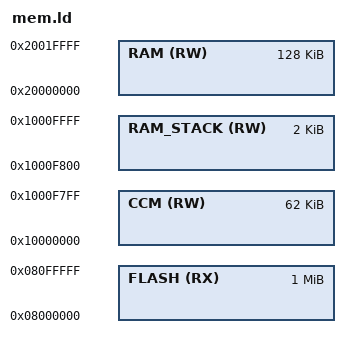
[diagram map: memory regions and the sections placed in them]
MEMORY
{
    FLASH (RX)     : ORIGIN = 0x08000000, LENGTH = 1024K
    CCM (RW)       : ORIGIN = 0x10000000, LENGTH = 62K
    RAM_STACK (RW) : ORIGIN = 0x1000F800, LENGTH = 2K
    RAM (RW)       : ORIGIN = 0x20000000, LENGTH = 128K
}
